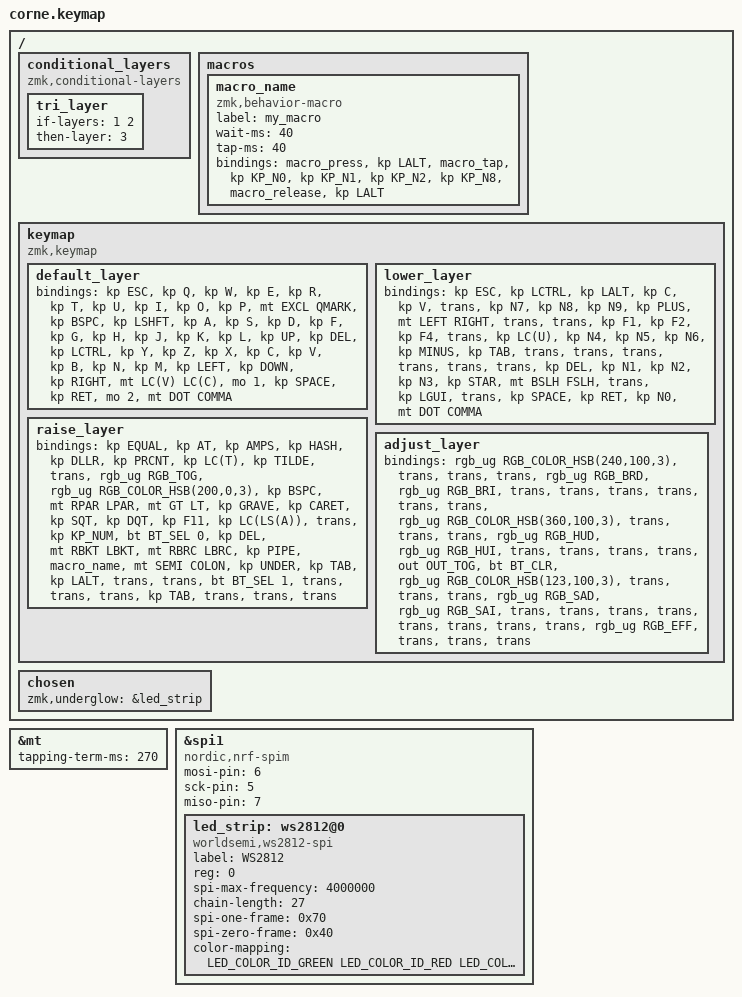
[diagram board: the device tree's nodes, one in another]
/*
 * Copyright (c) 2020 The ZMK Contributors
 *
 * SPDX-License-Identifier: MIT
 */
 
#include <dt-bindings/led/led.h>
#include <behaviors.dtsi>
#include <dt-bindings/zmk/keys.h>
#include <dt-bindings/zmk/bt.h>
#include <dt-bindings/zmk/rgb.h>
#include <dt-bindings/zmk/backlight.h>
#include <dt-bindings/zmk/outputs.h>




&mt {
    tapping-term-ms = <270>;
};

/ {
    conditional_layers {
        compatible = "zmk,conditional-layers";
        tri_layer {
            if-layers = <1 2>;
            then-layer = <3>;
        };
  };
  
  macros {
    macro_name: macro_name {
        label = "my_macro";
        compatible = "zmk,behavior-macro";
        #binding-cells = <0>;
        wait-ms = <40>;
        tap-ms = <40>;
        bindings
        = <&macro_press   &kp LALT>
        , <&macro_tap     &kp KP_N0 &kp KP_N1 &kp KP_N2 &kp KP_N8>
        , <&macro_release &kp LALT>
        ;
    };
};

        keymap {
                compatible = "zmk,keymap";

                default_layer {

                        bindings = <
                    
&kp ESC &kp Q &kp W &kp E &kp R &kp T &kp U &kp I &kp O &kp P &mt EXCL QMARK &kp BSPC &kp LSHFT &kp A &kp S &kp D &kp F &kp G &kp H &kp J &kp K &kp L &kp UP &kp DEL &kp LCTRL &kp Y &kp Z &kp X &kp C &kp V &kp B &kp N &kp M &kp LEFT &kp DOWN &kp RIGHT &mt LC(V) LC(C) &mo 1 &kp SPACE &kp RET &mo 2 &mt DOT COMMA
>;
             };
              
                lower_layer {
                
                        bindings = <
                 
&kp ESC &kp LCTRL &kp LALT &kp C &kp V &trans &kp N7 &kp N8 &kp N9 &kp PLUS &mt LEFT RIGHT &trans &trans &kp F1 &kp F2 &kp F4 &trans &kp LC(U) &kp N4 &kp N5 &kp N6 &kp MINUS &kp TAB &trans &trans &trans &trans &trans &trans &kp DEL &kp N1 &kp N2 &kp N3 &kp STAR &mt BSLH FSLH &trans &kp LGUI &trans &kp SPACE &kp RET &kp N0 &mt DOT COMMA
>;
               };
                raise_layer {
                
                        bindings = <
                   
&kp EQUAL &kp AT &kp AMPS &kp HASH &kp DLLR &kp PRCNT &kp LC(T) &kp TILDE &trans &rgb_ug RGB_TOG &rgb_ug RGB_COLOR_HSB(200,0,3) &kp BSPC &mt RPAR LPAR &mt GT LT &kp GRAVE &kp CARET &kp SQT &kp DQT &kp F11 &kp LC(LS(A)) &trans &kp KP_NUM &bt BT_SEL 0 &kp DEL &mt RBKT LBKT &mt RBRC LBRC &kp PIPE &macro_name &mt SEMI COLON &kp UNDER &kp TAB &kp LALT &trans &trans &bt BT_SEL 1 &trans &trans &trans &kp TAB &trans &trans &trans
>; 
                };
               
               adjust_layer {
                
                        bindings = <
                   
&rgb_ug RGB_COLOR_HSB(240,100,3) &trans &trans &trans &rgb_ug RGB_BRD &rgb_ug RGB_BRI &trans &trans &trans &trans &trans &trans &rgb_ug RGB_COLOR_HSB(360,100,3) &trans &trans &trans &rgb_ug RGB_HUD &rgb_ug RGB_HUI &trans &trans &trans &trans &out OUT_TOG &bt BT_CLR &rgb_ug RGB_COLOR_HSB(123,100,3) &trans &trans &trans &rgb_ug RGB_SAD &rgb_ug RGB_SAI &trans &trans &trans &trans &trans &trans &trans &trans &rgb_ug RGB_EFF &trans &trans &trans
>; 
                   };
            };
      };


// -----------------------------------------------------------------------------------------
// color picker for HSB color system http://colorizer.org/
// check your power consumption here https://zmk.dev/power-profiler/
// -----------------------------------------------------------------------------------------

// deemen17: I copied this from Ardakilic 
// https://github.com/Ardakilic/zmk-config/blob/master/config/reviung41.keymap

/*
 * Temporarily here because nice nano v2 spi is not defined on ZMK Yet 
 * Source: https://github.com/zmkfirmware/zmk/blob/main/app/boards/shields/reviung41/boards/nice_nano.overlay
 * GitHub Issue: https://github.com/zmkfirmware/zmk/issues/885
 */
 
&spi1 {
   compatible = "nordic,nrf-spim";
   status = "okay";

   mosi-pin = <6>;

   // Unused pins, needed for SPI definition, but not used by the ws2812 driver itself.
   sck-pin = <5>;
   miso-pin = <7>;

   led_strip: ws2812@0 {
      compatible = "worldsemi,ws2812-spi";
      label = "WS2812";

      /* SPI */
      reg = <0>; /* ignored, but necessary for SPI bindings */
      spi-max-frequency = <4000000>;

      /* WS2812 */
      chain-length = <27>; /* arbitrary; change at will */
      spi-one-frame = <0x70>;
      spi-zero-frame = <0x40>;
       color-mapping = <LED_COLOR_ID_GREEN
                   LED_COLOR_ID_RED
                   LED_COLOR_ID_BLUE>;
   };
};

/ {
   chosen {
      zmk,underglow = &led_strip;
   };
};


